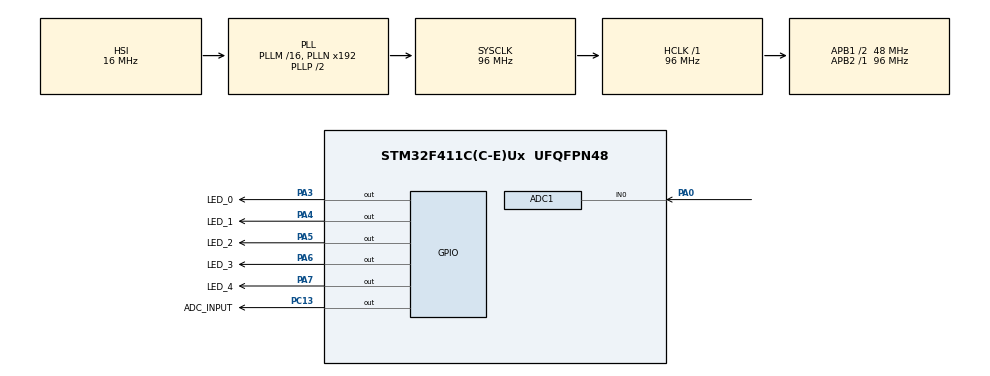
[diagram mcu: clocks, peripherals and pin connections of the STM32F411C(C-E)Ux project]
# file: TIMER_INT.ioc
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ADC1.Channel-0\#ChannelRegularConversion=ADC_CHANNEL_0
ADC1.NbrOfConversionFlag=1
ADC1.Rank-0\#ChannelRegularConversion=1
ADC1.SamplingTime-0\#ChannelRegularConversion=ADC_SAMPLETIME_3CYCLES
ADC1.master=1
Mcu.Family=STM32F4
Mcu.Name=STM32F411C(C-E)Ux
Mcu.Package=UFQFPN48
NVIC.PriorityGroup=NVIC_PRIORITYGROUP_4
PA0-WKUP.Signal=ADCx_IN0
PA14.Signal=SYS_JTCK-SWCLK
PA3.GPIO_Label=LED_0
PA3.Signal=GPIO_Output
PA4.GPIO_Label=LED_1
PA4.Signal=GPIO_Output
PA5.GPIO_Label=LED_2
PA5.Signal=GPIO_Output
PA6.GPIO_Label=LED_3
PA6.Signal=GPIO_Output
PA7.GPIO_Label=LED_4
PA7.Signal=GPIO_Output
PC13-ANTI_TAMP.GPIO_Label=ADC_INPUT
PC13-ANTI_TAMP.Signal=GPIO_Output
ProjectManager.HeapSize=0x200
ProjectManager.StackSize=0x400
ProjectManager.TargetToolchain=EWARM V8.50
RCC.48MHZClocksFreq_Value=48000000
RCC.AHBFreq_Value=96000000
RCC.APB1CLKDivider=RCC_HCLK_DIV2
RCC.APB1Freq_Value=48000000
RCC.APB1TimFreq_Value=96000000
RCC.APB2Freq_Value=96000000
RCC.APB2TimFreq_Value=96000000
RCC.CortexFreq_Value=96000000
RCC.HCLKFreq_Value=96000000
RCC.HSE_VALUE=25000000
RCC.HSI_VALUE=16000000
RCC.LSE_VALUE=32768
RCC.SYSCLKFreq_VALUE=96000000
RCC.SYSCLKSource=RCC_SYSCLKSOURCE_PLLCLK
RCC.VCOOutputFreq_Value=192000000
SH.ADCx_IN0.0=ADC1_IN0,IN0
board=custom

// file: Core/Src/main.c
/* USER CODE BEGIN Header */
/**
  ******************************************************************************
  * @file           : main.c
  * @brief          : Main program body
  ******************************************************************************
  * @attention
  *
  * Copyright (c) 2025 STMicroelectronics.
  * All rights reserved.
  *
  * This software is licensed under terms that can be found in the LICENSE file
  * in the root directory of this software component.
  * If no LICENSE file comes with this software, it is provided AS-IS.
  *
  ******************************************************************************
  */
/* USER CODE END Header */
#include "main.h"

ADC_HandleTypeDef hadc1;

void SystemClock_Config(void);
static void MX_GPIO_Init(void);
static void MX_ADC1_Init(void);

/* USER CODE BEGIN 0 */

uint32_t adc_value = 0;

uint32_t min_adc_value = 0;
uint32_t max_adc_value = 4095; // Assuming 12-bit ADC resolution

uint8_t led_brightness = 0; // Initial brightness level

uint16_t leds[5] = {LED_0_Pin, LED_1_Pin, LED_2_Pin, LED_3_Pin, LED_4_Pin};

/* USER CODE END 0 */

int main(void)
{

  /* MCU Configuration--------------------------------------------------------*/

  /* Reset of all peripherals, Initializes the Flash interface and the Systick. */
  HAL_Init();

  /* Configure the system clock */
  SystemClock_Config();

  /* Initialize all configured peripherals */
  MX_GPIO_Init();
  MX_ADC1_Init();
  /* USER CODE BEGIN 2 */

   // Start ADC conversion

  /* USER CODE END 2 */

  /* Infinite loop */
  while (1)
  {
    HAL_ADC_Start(&hadc1);
    HAL_ADC_PollForConversion(&hadc1, 100);
    adc_value = HAL_ADC_GetValue(&hadc1); // Read ADC value

    led_brightness = (int) 5*(adc_value - min_adc_value)/(max_adc_value - min_adc_value);

    for (int i = 0; i < led_brightness; i++) {
      HAL_GPIO_WritePin(GPIOA, leds[i], GPIO_PIN_RESET); // Turn on LEDs based on brightness level
    }

    for (int i = led_brightness; i < 5; i++) {
      HAL_GPIO_WritePin(GPIOA, leds[i], GPIO_PIN_SET); // Ensure remaining LEDs are off
    }

    HAL_Delay(50); // Delay for stability, adjust as needed

  }
}

void SystemClock_Config(void)
{
  RCC_OscInitTypeDef RCC_OscInitStruct = {0};
  RCC_ClkInitTypeDef RCC_ClkInitStruct = {0};

  /** Configure the main internal regulator output voltage
  */
  __HAL_RCC_PWR_CLK_ENABLE();
  __HAL_PWR_VOLTAGESCALING_CONFIG(PWR_REGULATOR_VOLTAGE_SCALE1);

  /** Initializes the RCC Oscillators according to the specified parameters
  * in the RCC_OscInitTypeDef structure.
  */
  RCC_OscInitStruct.OscillatorType = RCC_OSCILLATORTYPE_HSI;
  RCC_OscInitStruct.HSIState = RCC_HSI_ON;
  RCC_OscInitStruct.HSICalibrationValue = RCC_HSICALIBRATION_DEFAULT;
  RCC_OscInitStruct.PLL.PLLState = RCC_PLL_ON;
  RCC_OscInitStruct.PLL.PLLSource = RCC_PLLSOURCE_HSI;
  RCC_OscInitStruct.PLL.PLLM = 16;
  RCC_OscInitStruct.PLL.PLLN = 192;
  RCC_OscInitStruct.PLL.PLLP = RCC_PLLP_DIV2;
  RCC_OscInitStruct.PLL.PLLQ = 4;
  if (HAL_RCC_OscConfig(&RCC_OscInitStruct) != HAL_OK)
  {
    Error_Handler();
  }

  /** Initializes the CPU, AHB and APB buses clocks
  */
  RCC_ClkInitStruct.ClockType = RCC_CLOCKTYPE_HCLK|RCC_CLOCKTYPE_SYSCLK
                              |RCC_CLOCKTYPE_PCLK1|RCC_CLOCKTYPE_PCLK2;
  RCC_ClkInitStruct.SYSCLKSource = RCC_SYSCLKSOURCE_PLLCLK;
  RCC_ClkInitStruct.AHBCLKDivider = RCC_SYSCLK_DIV1;
  RCC_ClkInitStruct.APB1CLKDivider = RCC_HCLK_DIV2;
  RCC_ClkInitStruct.APB2CLKDivider = RCC_HCLK_DIV1;

  if (HAL_RCC_ClockConfig(&RCC_ClkInitStruct, FLASH_LATENCY_3) != HAL_OK)
  {
    Error_Handler();
  }
}

static void MX_ADC1_Init(void)
{

  ADC_ChannelConfTypeDef sConfig = {0};

  /** Configure the global features of the ADC (Clock, Resolution, Data Alignment and number of conversion)
  */
  hadc1.Instance = ADC1;
  hadc1.Init.ClockPrescaler = ADC_CLOCK_SYNC_PCLK_DIV4;
  hadc1.Init.Resolution = ADC_RESOLUTION_12B;
  hadc1.Init.ScanConvMode = DISABLE;
  hadc1.Init.ContinuousConvMode = DISABLE;
  hadc1.Init.DiscontinuousConvMode = DISABLE;
  hadc1.Init.ExternalTrigConvEdge = ADC_EXTERNALTRIGCONVEDGE_NONE;
  hadc1.Init.ExternalTrigConv = ADC_SOFTWARE_START;
  hadc1.Init.DataAlign = ADC_DATAALIGN_RIGHT;
  hadc1.Init.NbrOfConversion = 1;
  hadc1.Init.DMAContinuousRequests = DISABLE;
  hadc1.Init.EOCSelection = ADC_EOC_SINGLE_CONV;
  if (HAL_ADC_Init(&hadc1) != HAL_OK)
  {
    Error_Handler();
  }

  /** Configure for the selected ADC regular channel its corresponding rank in the sequencer and its sample time.
  */
  sConfig.Channel = ADC_CHANNEL_0;
  sConfig.Rank = 1;
  sConfig.SamplingTime = ADC_SAMPLETIME_3CYCLES;
  if (HAL_ADC_ConfigChannel(&hadc1, &sConfig) != HAL_OK)
  {
    Error_Handler();
  }

}

static void MX_GPIO_Init(void)
{
  GPIO_InitTypeDef GPIO_InitStruct = {0};

  /* GPIO Ports Clock Enable */
  __HAL_RCC_GPIOC_CLK_ENABLE();
  __HAL_RCC_GPIOA_CLK_ENABLE();

  /*Configure GPIO pin Output Level */
  HAL_GPIO_WritePin(ADC_INPUT_GPIO_Port, ADC_INPUT_Pin, GPIO_PIN_RESET);

  /*Configure GPIO pin Output Level */
  HAL_GPIO_WritePin(GPIOA, LED_0_Pin|LED_1_Pin|LED_2_Pin|LED_3_Pin
                          |LED_4_Pin, GPIO_PIN_RESET);

  /*Configure GPIO pin : ADC_INPUT_Pin */
  GPIO_InitStruct.Pin = ADC_INPUT_Pin;
  GPIO_InitStruct.Mode = GPIO_MODE_OUTPUT_PP;
  GPIO_InitStruct.Pull = GPIO_NOPULL;
  GPIO_InitStruct.Speed = GPIO_SPEED_FREQ_LOW;
  HAL_GPIO_Init(ADC_INPUT_GPIO_Port, &GPIO_InitStruct);

  /*Configure GPIO pins : LED_0_Pin LED_1_Pin LED_2_Pin LED_3_Pin
                           LED_4_Pin */
  GPIO_InitStruct.Pin = LED_0_Pin|LED_1_Pin|LED_2_Pin|LED_3_Pin
                          |LED_4_Pin;
  GPIO_InitStruct.Mode = GPIO_MODE_OUTPUT_PP;
  GPIO_InitStruct.Pull = GPIO_NOPULL;
  GPIO_InitStruct.Speed = GPIO_SPEED_FREQ_LOW;
  HAL_GPIO_Init(GPIOA, &GPIO_InitStruct);

}

void Error_Handler(void)
{
  __disable_irq();
  while (1)
  {
  }
}
